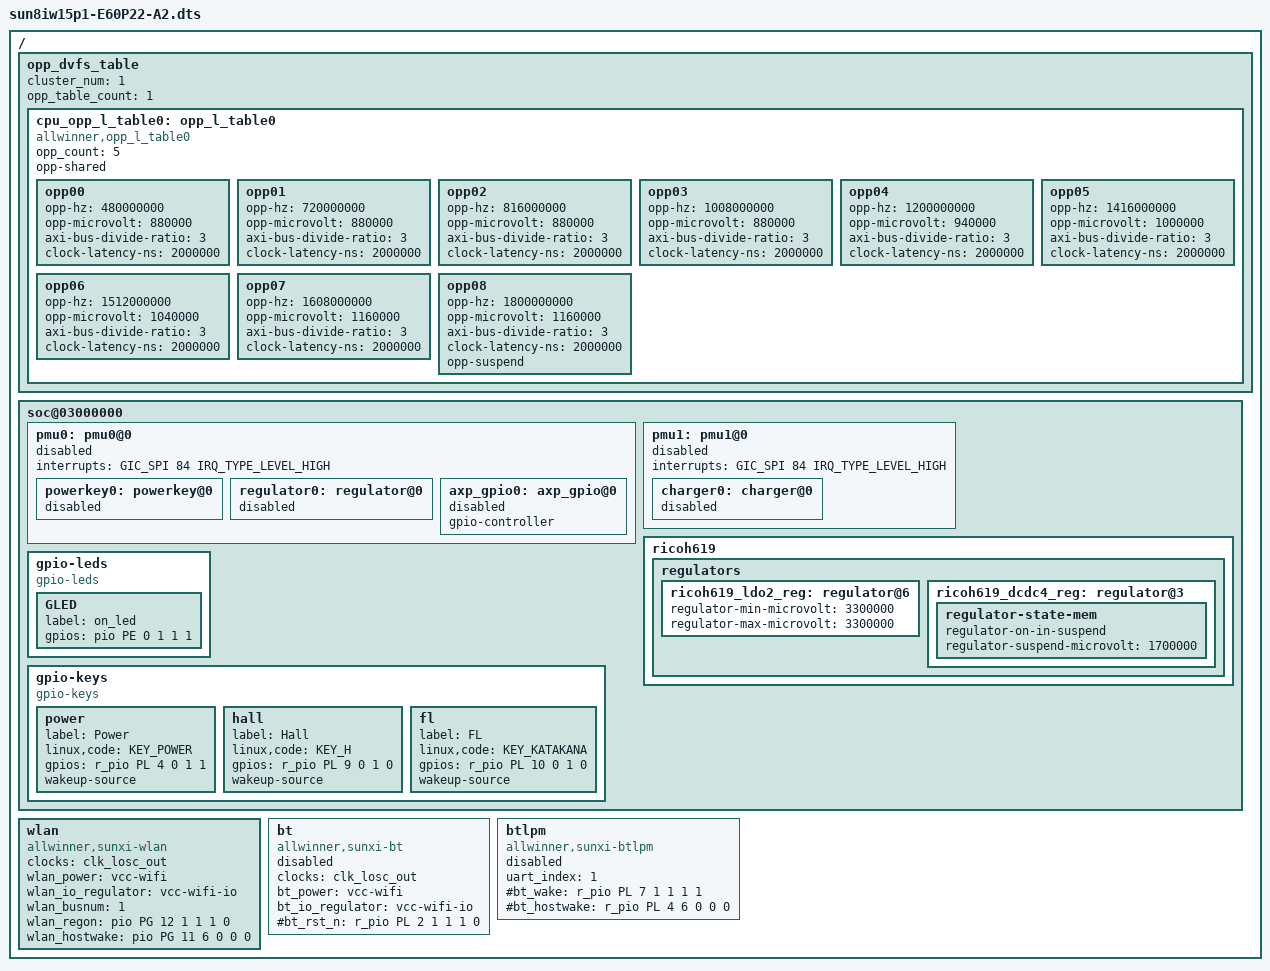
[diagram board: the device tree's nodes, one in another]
/*
 * Allwinner Technology CO., Ltd. sun8iw15p1 soc board.
 *
 * soc board support.
 */

/dts-v1/;

#include "sun8iw15p1-eink_128m.dtsi"
#include "sun8iw15p1-ntx_common.dtsi"

/{

opp_dvfs_table:opp_dvfs_table {
		cluster_num = <1>;
		opp_table_count = <1>;

		cpu_opp_l_table0: opp_l_table0 {
			/* compatible = "operating-points-v2"; */
			compatible = "allwinner,opp_l_table0";
			opp_count = <5>;
			opp-shared;

			opp00 {
				opp-hz = /bits/ 64 <480000000>;
				opp-microvolt = <880000>;
				axi-bus-divide-ratio = <3>;
				clock-latency-ns = <2000000>;
			};

			opp01 {
				opp-hz = /bits/ 64 <720000000>;
				opp-microvolt = <880000>;
				axi-bus-divide-ratio = <3>;
				clock-latency-ns = <2000000>;
			};

			opp02 {
				opp-hz = /bits/ 64 <816000000>;
				opp-microvolt = <880000>;
				axi-bus-divide-ratio = <3>;
				clock-latency-ns = <2000000>;
			};

			opp03 {
				opp-hz = /bits/ 64 <1008000000>;
				opp-microvolt = <880000>;
				axi-bus-divide-ratio = <3>;
				clock-latency-ns = <2000000>;
			};

			opp04 {
				opp-hz = /bits/ 64 <1200000000>;
				opp-microvolt = <940000>;
				axi-bus-divide-ratio = <3>;
				clock-latency-ns = <2000000>;
			};

			opp05 {
				opp-hz = /bits/ 64 <1416000000>;
				opp-microvolt = <1000000>;
				axi-bus-divide-ratio = <3>;
				clock-latency-ns = <2000000>;
			};

			opp06 {
				opp-hz = /bits/ 64 <1512000000>;
				opp-microvolt = <1040000>;
				axi-bus-divide-ratio = <3>;
				clock-latency-ns = <2000000>;
			};

			opp07 {
				opp-hz = /bits/ 64 <1608000000>;
				opp-microvolt = <1160000>;
				axi-bus-divide-ratio = <3>;
				clock-latency-ns = <2000000>;
			};

			opp08 {
				opp-hz = /bits/ 64 <1800000000>;
				opp-microvolt = <1160000>;
				axi-bus-divide-ratio = <3>;
				clock-latency-ns = <2000000>;
				opp-suspend;
			};
		};
	};
	soc@03000000 {
		pmu0: pmu0@0{
			interrupts = <GIC_SPI 84 IRQ_TYPE_LEVEL_HIGH>;
			status = "disabled";

			powerkey0: powerkey@0{
				status = "disabled";
			};

			regulator0: regulator@0{
				status = "disabled";
			};

			axp_gpio0: axp_gpio@0{
				gpio-controller;
				#size-cells = <0>;
				#gpio-cells = <6>;
				status = "disabled";
			};

		};

		pmu1: pmu1@0{
			interrupts = <GIC_SPI 84 IRQ_TYPE_LEVEL_HIGH>;
			status = "disabled";
			device_type = "pmu1";

			charger0: charger@0{
				status = "disabled";
			};
		};

#include "ricoh619_b300.dtsi"
		ricoh619 {
			regulators {
				ricoh619_ldo2_reg: regulator@6  {
					regulator-min-microvolt = <3300000>;
					regulator-max-microvolt = <3300000>;
				};
				ricoh619_dcdc4_reg: regulator@3 {
					regulator-state-mem {
						regulator-on-in-suspend;
						regulator-suspend-microvolt = <1700000>;
					};
				};
			};
		};
		gpio-leds {
			compatible = "gpio-leds";

			GLED {
				label = "on_led";
				gpios = <&pio PE 0 1 1 1 1>;
			};
		};

		gpio-keys {
			compatible = "gpio-keys";

			power {
				label = "Power";
				linux,code = <KEY_POWER>;
				gpios = <&r_pio PL 4 0 1 1 1>;		
				wakeup-source;
			};

			hall {
				label = "Hall";
				linux,code = <KEY_H>;
				gpios = <&r_pio PL 9 0 1 0 1>;
				wakeup-source;
			};

			fl {
				label = "FL";
				linux,code = <KEY_KATAKANA>;
				gpios = <&r_pio PL 10 0 1 0 1>;
				wakeup-source;
			};
		};
	};

	wlan:wlan {
		compatible = "allwinner,sunxi-wlan";
		clocks = <&clk_losc_out>;
		wlan_power = "vcc-wifi";
		wlan_io_regulator = "vcc-wifi-io";
		wlan_busnum = <1>;
		wlan_regon = <&pio PG 12 1 1 1 0>;
		wlan_hostwake = <&pio PG 11 6 0 0 0>;
		status = "okay";
	};

	bt:bt {
		compatible = "allwinner,sunxi-bt";
		clocks = <&clk_losc_out>;
		bt_power = "vcc-wifi";
		bt_io_regulator = "vcc-wifi-io";
		#bt_rst_n = <&r_pio PL 2 1 1 1 0>;
		status = "disabled";
	};

	btlpm:btlpm {
		compatible = "allwinner,sunxi-btlpm";
		uart_index = <1>;
		#bt_wake = <&r_pio PL 7 1 1 1 1>;
		#bt_hostwake = <&r_pio PL 4 6 0 0 0>;
		status = "disabled";
	};

};
